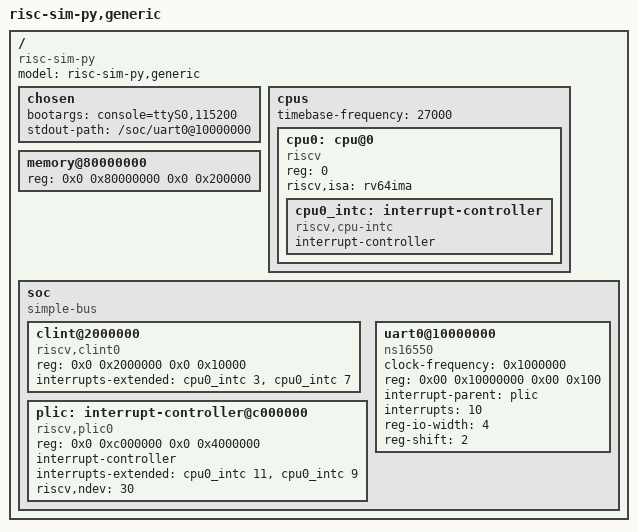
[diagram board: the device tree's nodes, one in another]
/dts-v1/;

/ {
    #address-cells = <2>;
    #size-cells = <2>;
    compatible = "risc-sim-py";
    model = "risc-sim-py,generic";

    chosen {
        bootargs = "console=ttyS0,115200";
        stdout-path = "/soc/uart0@10000000";
    };

    cpus {
        #address-cells = <1>;
        #size-cells = <0>;

        // based on instruction ececution 272kHz clint incremented every 10 operation so roughly 27kHz
        timebase-frequency = <27000>; 

        cpu0: cpu@0 {
            device_type = "cpu";
            reg = <0>;
            status = "okay";
            compatible = "riscv";
            riscv,isa = "rv64ima"; // Adjust based on your CPU
            // clock-frequency = <100000000>; // 100 MHz, adjust as needed

            cpu0_intc: interrupt-controller {
                #interrupt-cells = <1>;
                interrupt-controller;
                compatible = "riscv,cpu-intc";
            };
        };
    };

    memory@80000000 {
        device_type = "memory";
        reg = <0x0 0x80000000 0x0 0x200000>; // 128 MB, adjust as needed
    };

    soc {
        #address-cells = <2>;
        #size-cells = <2>;
        compatible = "simple-bus";
        ranges;

        clint@2000000 {
            compatible = "riscv,clint0";
            reg = <0x0 0x2000000 0x0 0x10000>;
            interrupts-extended = <&cpu0_intc 3 &cpu0_intc 7>;
        };

        plic: interrupt-controller@c000000 {
            compatible = "riscv,plic0";
            reg = <0x0 0xc000000 0x0 0x4000000>;
            #interrupt-cells = <1>;
            interrupt-controller;
            interrupts-extended = <&cpu0_intc 11 &cpu0_intc 9>;
            riscv,ndev = <30>; // Number of interrupt sources, adjust as needed
        };


        uart0@10000000 {
            clock-frequency = <0x1000000>;
            reg = <0x00 0x10000000 0x00 0x100>;
            compatible = "ns16550";
            interrupt-parent = <&plic>;
            interrupts = <10>;
            reg-io-width = <4>;
            reg-shift = <2>;
        };
    };
};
